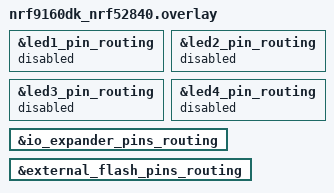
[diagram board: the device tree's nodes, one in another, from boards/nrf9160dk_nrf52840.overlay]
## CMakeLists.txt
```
# /* The Clear BSD License
#  *
#  * Copyright (c) 2025 EdgeImpulse Inc.
#  * All rights reserved.
#  *
#  * Redistribution and use in source and binary forms, with or without
#  * modification, are permitted (subject to the limitations in the disclaimer
#  * below) provided that the following conditions are met:
#  *
#  *   * Redistributions of source code must retain the above copyright notice,
#  *   this list of conditions and the following disclaimer.
#  *
#  *   * Redistributions in binary form must reproduce the above copyright
#  *   notice, this list of conditions and the following disclaimer in the
#  *   documentation and/or other materials provided with the distribution.
#  *
#  *   * Neither the name of the copyright holder nor the names of its
#  *   contributors may be used to endorse or promote products derived from this
#  *   software without specific prior written permission.
#  *
#  * NO EXPRESS OR IMPLIED LICENSES TO ANY PARTY'S PATENT RIGHTS ARE GRANTED BY
#  * THIS LICENSE. THIS SOFTWARE IS PROVIDED BY THE COPYRIGHT HOLDERS AND
#  * CONTRIBUTORS "AS IS" AND ANY EXPRESS OR IMPLIED WARRANTIES, INCLUDING, BUT NOT
#  * LIMITED TO, THE IMPLIED WARRANTIES OF MERCHANTABILITY AND FITNESS FOR A
#  * PARTICULAR PURPOSE ARE DISCLAIMED. IN NO EVENT SHALL THE COPYRIGHT HOLDER OR
#  * CONTRIBUTORS BE LIABLE FOR ANY DIRECT, INDIRECT, INCIDENTAL, SPECIAL,
#  * EXEMPLARY, OR CONSEQUENTIAL DAMAGES (INCLUDING, BUT NOT LIMITED TO,
#  * PROCUREMENT OF SUBSTITUTE GOODS OR SERVICES; LOSS OF USE, DATA, OR PROFITS; OR
#  * BUSINESS INTERRUPTION) HOWEVER CAUSED AND ON ANY THEORY OF LIABILITY, WHETHER
#  * IN CONTRACT, STRICT LIABILITY, OR TORT (INCLUDING NEGLIGENCE OR OTHERWISE)
#  * ARISING IN ANY WAY OUT OF THE USE OF THIS SOFTWARE, EVEN IF ADVISED OF THE
#  * POSSIBILITY OF SUCH DAMAGE.
#  */

cmake_minimum_required(VERSION 3.13.1)
find_package(Zephyr REQUIRED HINTS $ENV{ZEPHYR_BASE})
project(board-controller)

target_sources(app PRIVATE src/main.c)
```

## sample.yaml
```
sample:
  name: Board Controller for nRF9160 DK >0.14.0
```

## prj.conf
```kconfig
# /* The Clear BSD License
#  *
#  * Copyright (c) 2025 EdgeImpulse Inc.
#  * All rights reserved.
#  *
#  * Redistribution and use in source and binary forms, with or without
#  * modification, are permitted (subject to the limitations in the disclaimer
#  * below) provided that the following conditions are met:
#  *
#  *   * Redistributions of source code must retain the above copyright notice,
#  *   this list of conditions and the following disclaimer.
#  *
#  *   * Redistributions in binary form must reproduce the above copyright
#  *   notice, this list of conditions and the following disclaimer in the
#  *   documentation and/or other materials provided with the distribution.
#  *
#  *   * Neither the name of the copyright holder nor the names of its
#  *   contributors may be used to endorse or promote products derived from this
#  *   software without specific prior written permission.
#  *
#  * NO EXPRESS OR IMPLIED LICENSES TO ANY PARTY'S PATENT RIGHTS ARE GRANTED BY
#  * THIS LICENSE. THIS SOFTWARE IS PROVIDED BY THE COPYRIGHT HOLDERS AND
#  * CONTRIBUTORS "AS IS" AND ANY EXPRESS OR IMPLIED WARRANTIES, INCLUDING, BUT NOT
#  * LIMITED TO, THE IMPLIED WARRANTIES OF MERCHANTABILITY AND FITNESS FOR A
#  * PARTICULAR PURPOSE ARE DISCLAIMED. IN NO EVENT SHALL THE COPYRIGHT HOLDER OR
#  * CONTRIBUTORS BE LIABLE FOR ANY DIRECT, INDIRECT, INCIDENTAL, SPECIAL,
#  * EXEMPLARY, OR CONSEQUENTIAL DAMAGES (INCLUDING, BUT NOT LIMITED TO,
#  * PROCUREMENT OF SUBSTITUTE GOODS OR SERVICES; LOSS OF USE, DATA, OR PROFITS; OR
#  * BUSINESS INTERRUPTION) HOWEVER CAUSED AND ON ANY THEORY OF LIABILITY, WHETHER
#  * IN CONTRACT, STRICT LIABILITY, OR TORT (INCLUDING NEGLIGENCE OR OTHERWISE)
#  * ARISING IN ANY WAY OUT OF THE USE OF THIS SOFTWARE, EVEN IF ADVISED OF THE
#  * POSSIBILITY OF SUCH DAMAGE.
#  */

CONFIG_GPIO=y
```

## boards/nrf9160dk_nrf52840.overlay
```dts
/* The Clear BSD License
 *
 * Copyright (c) 2025 EdgeImpulse Inc.
 * All rights reserved.
 *
 * Redistribution and use in source and binary forms, with or without
 * modification, are permitted (subject to the limitations in the disclaimer
 * below) provided that the following conditions are met:
 *
 *   * Redistributions of source code must retain the above copyright notice,
 *   this list of conditions and the following disclaimer.
 *
 *   * Redistributions in binary form must reproduce the above copyright
 *   notice, this list of conditions and the following disclaimer in the
 *   documentation and/or other materials provided with the distribution.
 *
 *   * Neither the name of the copyright holder nor the names of its
 *   contributors may be used to endorse or promote products derived from this
 *   software without specific prior written permission.
 *
 * NO EXPRESS OR IMPLIED LICENSES TO ANY PARTY'S PATENT RIGHTS ARE GRANTED BY
 * THIS LICENSE. THIS SOFTWARE IS PROVIDED BY THE COPYRIGHT HOLDERS AND
 * CONTRIBUTORS "AS IS" AND ANY EXPRESS OR IMPLIED WARRANTIES, INCLUDING, BUT NOT
 * LIMITED TO, THE IMPLIED WARRANTIES OF MERCHANTABILITY AND FITNESS FOR A
 * PARTICULAR PURPOSE ARE DISCLAIMED. IN NO EVENT SHALL THE COPYRIGHT HOLDER OR
 * CONTRIBUTORS BE LIABLE FOR ANY DIRECT, INDIRECT, INCIDENTAL, SPECIAL,
 * EXEMPLARY, OR CONSEQUENTIAL DAMAGES (INCLUDING, BUT NOT LIMITED TO,
 * PROCUREMENT OF SUBSTITUTE GOODS OR SERVICES; LOSS OF USE, DATA, OR PROFITS; OR
 * BUSINESS INTERRUPTION) HOWEVER CAUSED AND ON ANY THEORY OF LIABILITY, WHETHER
 * IN CONTRACT, STRICT LIABILITY, OR TORT (INCLUDING NEGLIGENCE OR OTHERWISE)
 * ARISING IN ANY WAY OUT OF THE USE OF THIS SOFTWARE, EVEN IF ADVISED OF THE
 * POSSIBILITY OF SUCH DAMAGE.
 */

&led1_pin_routing {
    status = "disabled";
};

&led2_pin_routing {
    status = "disabled";
};

&led3_pin_routing {
    status = "disabled";
};

&led4_pin_routing {
    status = "disabled";
};

&io_expander_pins_routing {
    status = "okay";
};

&external_flash_pins_routing {
    status = "okay";
};
```

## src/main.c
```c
/* The Clear BSD License
 *
 * Copyright (c) 2025 EdgeImpulse Inc.
 * All rights reserved.
 *
 * Redistribution and use in source and binary forms, with or without
 * modification, are permitted (subject to the limitations in the disclaimer
 * below) provided that the following conditions are met:
 *
 *   * Redistributions of source code must retain the above copyright notice,
 *   this list of conditions and the following disclaimer.
 *
 *   * Redistributions in binary form must reproduce the above copyright
 *   notice, this list of conditions and the following disclaimer in the
 *   documentation and/or other materials provided with the distribution.
 *
 *   * Neither the name of the copyright holder nor the names of its
 *   contributors may be used to endorse or promote products derived from this
 *   software without specific prior written permission.
 *
 * NO EXPRESS OR IMPLIED LICENSES TO ANY PARTY'S PATENT RIGHTS ARE GRANTED BY
 * THIS LICENSE. THIS SOFTWARE IS PROVIDED BY THE COPYRIGHT HOLDERS AND
 * CONTRIBUTORS "AS IS" AND ANY EXPRESS OR IMPLIED WARRANTIES, INCLUDING, BUT NOT
 * LIMITED TO, THE IMPLIED WARRANTIES OF MERCHANTABILITY AND FITNESS FOR A
 * PARTICULAR PURPOSE ARE DISCLAIMED. IN NO EVENT SHALL THE COPYRIGHT HOLDER OR
 * CONTRIBUTORS BE LIABLE FOR ANY DIRECT, INDIRECT, INCIDENTAL, SPECIAL,
 * EXEMPLARY, OR CONSEQUENTIAL DAMAGES (INCLUDING, BUT NOT LIMITED TO,
 * PROCUREMENT OF SUBSTITUTE GOODS OR SERVICES; LOSS OF USE, DATA, OR PROFITS; OR
 * BUSINESS INTERRUPTION) HOWEVER CAUSED AND ON ANY THEORY OF LIABILITY, WHETHER
 * IN CONTRACT, STRICT LIABILITY, OR TORT (INCLUDING NEGLIGENCE OR OTHERWISE)
 * ARISING IN ANY WAY OUT OF THE USE OF THIS SOFTWARE, EVEN IF ADVISED OF THE
 * POSSIBILITY OF SUCH DAMAGE.
 */

#include <zephyr/kernel.h>

void main(void)
{
    while (1)
    {
        k_msleep(10);
    }
}
```
